# STM32L151xBA register map
File version: 1.0
Registers are 32-bit, read-write, reset 0x0 unless marked. A register's access mark holds for its fields unless they carry their own. Offsets are from the block's base; [hi:lo] are bit positions; {n}, {i} and the like mark numbered series; 'fields as' and 'values as' point back to an identical list.

## RTC — Real-Time Clock
Base 0x40002800
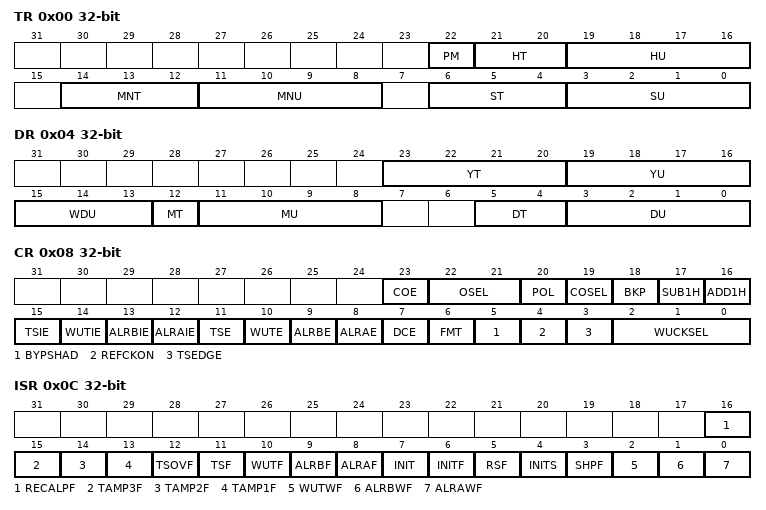
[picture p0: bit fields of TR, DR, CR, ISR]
0x00 TR — RTC time register
  [22] PM
    0=AM_OR_24 (AM or 24-hour format); 1=PM
  [21:20] HT
  [19:16] HU
  [14:12] MNT
  [11:8] MNU
  [6:4] ST
  [3:0] SU
0x04 DR — RTC date register
  [23:20] YT, [19:16] YU, [15:13] WDU, [12] MT, [11:8] MU, [5:4] DT, [3:0] DU
0x08 CR — RTC control register
  [23] COE
  [22:21] OSEL
    0=DISABLE (Output disabled); 1=ALMA (Alarm A output enabled); 2=ALMB (Alarm B output enabled); 3=WAKEUP (Wakeup output enabled)
  [20] POL
    0=HIGH (Pin is high when ALRAF/ALRBF/WUTF is asserted (depending on OSEL)); 1=LOW (Pin is low when ALRAF/ALRBF/WUTF is asserted (depending on OSEL))
  [19] COSEL
  [18] BKP
  [17] SUB1H
  [16] ADD1H
  [15] TSIE
  [14] WUTIE
  [13] ALRBIE
  [12] ALRAIE
  [11] TSE
  [10] WUTE
  [9] ALRBE
  [8] ALRAE
  [7] DCE
  [6] FMT
    0=HOURFORMAT_24HOUR (24 hour/day format); 1=AMPM (AM/PM hour format)
  [5] BYPSHAD
  [4] REFCKON
  [3] TSEDGE
    0=RISING (RTC_TS input rising edge generates a time-stamp event); 1=FALLING (RTC_TS input falling edge generates a time-stamp event)
  [2:0] WUCKSEL
    0=DIV_16 (RTC/16 clock is selected); 1=DIV_8 (RTC/8 clock is selected); 2=DIV_4 (RTC/4 clock is selected); 3=DIV_2 (RTC/2 clock is selected); 4=CKSPRE (ck_spre (usually 1 Hz) clock is selected); 6=CKSPRE_WUT (ck_spre (usually 1 Hz) clock is selected and 2exp16 is added to the WUT counter value)
0x0C ISR — RTC initialization and status register
  [16] RECALPF, [15] TAMP3F, [14] TAMP2F, [13] TAMP1F, [12] TSOVF, [11] TSF, [10] WUTF, [9] ALRBF, [8] ALRAF, [7] INIT, [6] INITF, [5] RSF, [4] INITS, [3] SHPF, [2] WUTWF, [1] ALRBWF, [0] ALRAWF
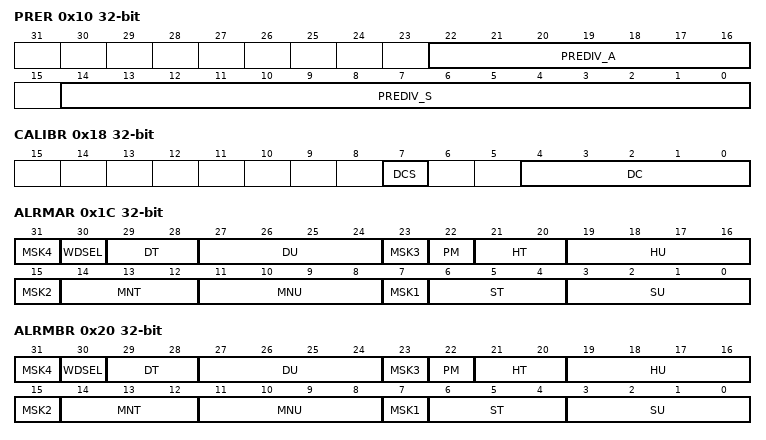
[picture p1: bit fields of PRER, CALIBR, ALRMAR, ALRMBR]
0x10 PRER — RTC prescaler register
  [22:16] PREDIV_A, [14:0] PREDIV_S
0x14 WUTR — RTC wakeup timer register
  [15:0] WUT
0x18 CALIBR — RTC calibration register
  [7] DCS
    0=POSITIVE (Positive calibration: calendar update frequency is increased); 1=NEGATIVE (Negative calibration: calendar update frequency is decreased)
  [4:0] DC
0x1C ALRMAR — RTC alarm A register
  [8n-1] MSK{n} (n=1..4)
  [30] WDSEL
  [29:28] DT
  [27:24] DU
  [22] PM
    0=AM (AM or 24-hour format); 1=PM
  [21:20] HT
  [19:16] HU
  [14:12] MNT
  [11:8] MNU
  [6:4] ST
  [3:0] SU
0x20 ALRMBR — RTC alarm B register
  fields as ALRMAR
0x24 WPR — RTC write protection register
  [7:0] KEY
0x28 SSR — RTC sub second register
  [15:0] SS
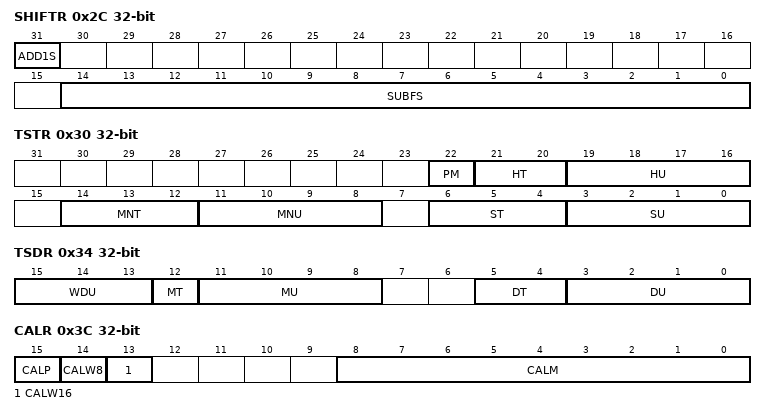
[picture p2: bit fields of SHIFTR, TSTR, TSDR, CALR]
0x2C SHIFTR — RTC shift control register
  [31] ADD1S, [14:0] SUBFS
0x30 TSTR — RTC time stamp time register
  [22] PM
    0=AM (AM or 24-hour format); 1=PM
  [21:20] HT
  [19:16] HU
  [14:12] MNT
  [11:8] MNU
  [6:4] ST
  [3:0] SU
0x34 TSDR — RTC time stamp date register
  [15:13] WDU, [12] MT, [11:8] MU, [5:4] DT, [3:0] DU
0x38 TSSSR — RTC time-stamp sub second register
  [15:0] SS
0x3C CALR — RRTC calibration register
  [15] CALP
    0=NONE (No RTCCLK pulses are added); 1=SET (One RTCCLK pulse is effectively inserted every 2exp11 pulses (frequency increased by 488.5 ppm))
  [14] CALW8
  [13] CALW16
  [8:0] CALM
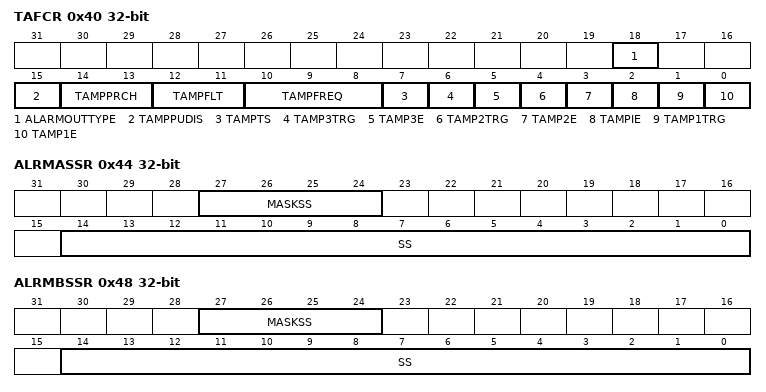
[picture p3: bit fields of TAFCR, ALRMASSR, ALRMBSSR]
0x40 TAFCR — RTC tamper and alternate function configuration register
  [18] ALARMOUTTYPE
    0=OPENDRAIN (RTC_ALARM, when mapped on PC13, is open-drain output); 1=PUSHPULL (RTC_ALARM, when mapped on PC13, is push-pull output)
  [15] TAMPPUDIS
  [14:13] TAMPPRCH
    0=DURATION_1RTCCLK (Tamper pins are pre-charged before sampling during 1 RTCCLK cycle); 1=DURATION_2RTCCLK (Tamper pins are pre-charged before sampling during 2 RTCCLK cycles); 2=DURATION_4RTCCLK (Tamper pins are pre-charged before sampling during 4 RTCCLK cycles); 3=DURATION_8RTCCLK (Tamper pins are pre-charged before sampling during 8 RTCCLK cycles)
  [12:11] TAMPFLT
    0=DISABLE (Tamper filter is disabled); 1=FILTER_2SAMPLE (Tamper is activated after 2 consecutive samples at the active level); 2=FILTER_4SAMPLE (Tamper is activated after 4 consecutive samples at the active level); 3=FILTER_8SAMPLE (Tamper is activated after 8 consecutive samples at the active level.)
  [10:8] TAMPFREQ
    0=SAMPLFREQDIV_32768 (Each of the tamper inputs are sampled with a frequency = RTCCLK / 32768); 1=SAMPLFREQDIV_16384 (Each of the tamper inputs are sampled with a frequency = RTCCLK / 16384); 2=SAMPLFREQDIV_8192 (Each of the tamper inputs are sampled with a frequency = RTCCLK / 8192); 3=SAMPLFREQDIV_4096 (Each of the tamper inputs are sampled with a frequency = RTCCLK / 4096); 4=SAMPLFREQDIV_2048 (Each of the tamper inputs are sampled with a frequency = RTCCLK / 2048); 5=SAMPLFREQDIV_1024 (Each of the tamper inputs are sampled with a frequency = RTCCLK / 1024); 6=SAMPLFREQDIV_512 (Each of the tamper inputs are sampled with a frequency = RTCCLK / 512); 7=SAMPLFREQDIV_256 (Each of the tamper inputs are sampled with a frequency = RTCCLK / 256)
  [7] TAMPTS
  [6] TAMP3TRG
  [5] TAMP3E
  [4] TAMP2TRG
  [3] TAMP2E
  [2] TAMPIE
  [1] TAMP1TRG
  [0] TAMP1E
0x44 ALRMASSR — RTC alarm A sub second register
  [27:24] MASKSS, [14:0] SS
0x48 ALRMBSSR — RTC alarm B sub second register
  [27:24] MASKSS, [14:0] SS
{0x50+4i} BKP{i}R (i=0..9) — RTC backup register {i}
{0x50+4i} BKP{i}R (i=10..19) — RTC backup register {i}
  [31:0] BKP1R
